AUTOSAR XML (schema 00045)
package /ara/phm
  platform health management contribution phmContrib: process=PhmSample_instance1
    11 x supervision checkpoint:
      engineInitializing: phm-checkpoint=PhmDemo.enginePrototype0.kInitializing
      engineStartupTest: phm-checkpoint=PhmDemo.enginePrototype0.kStartupTest
      engineInitializingFinished: phm-checkpoint=PhmDemo.enginePrototype0.kInitializingFinished
      wheelStarted: phm-checkpoint=PhmDemo.wheelPrototype0.kStarted
      wheelFinished: phm-checkpoint=PhmDemo.wheelPrototype0.kFinished
      wheelStarted: phm-checkpoint=PhmDemo.wheelPrototype1.kStarted
      wheelFinished: phm-checkpoint=PhmDemo.wheelPrototype1.kFinished
      wheelStarted: phm-checkpoint=PhmDemo.wheelPrototype2.kStarted
      wheelFinished: phm-checkpoint=PhmDemo.wheelPrototype2.kFinished
      wheelStarted: phm-checkpoint=PhmDemo.wheelPrototype3.kStarted
      wheelFinished: phm-checkpoint=PhmDemo.wheelPrototype3.kFinished
    global supervision suGlobal: expired-supervision-cycles-tolerance=1, supervision-cycle=0.0
      local supervision suLocal: failed-supervision-cycles-tolerance=0
        alive supervision alive: alive-reference-cycle=600, checkpoint=wheelRunning, expected-alive-indications=6, max-margin=10, min-margin=1
        deadline supervision deadline: checkpoint-transition=transition1, max-deadline=60, min-deadline=40
        logical supervision logical: initial-checkpoint=engineInitializing, final-checkpoint=engineInitializingFinished, transition=[transition1, transition2]
        checkpoint transition transition1: source=engineInitializing, target=engineStartupTest
        checkpoint transition transition2: source=engineStartupTest, target=engineInitializingFinished
        checkpoint transition deadlineTransition: source=phmContrib/wheelStarted, target=phmContrib/wheelFinished
    health channel supervision healthChannel: supervision-condition=IS-OK, supervision=suGlobal
    arbitration arbitration
      logical expression logExp: logical-operator=OR
      rule rule: expression=logExp, rule-init-state=FALSE
    action rec_action
      application action item app_action1: action-type=RESTART, process=PhmSample_instance1
      application action item app_action2: action-type=TERMINATE, process=PhmSample_instance1
      platform action item platform_action1: action-type=RESET-ECU
      platform action item platform_action2: action-type=RESET-MCU
      platform action item platform_action3: action-type=RESET-VM
      watchdog action item watchdog_action: action-type=STOP-TRIGGER
      action list action_list: action-list-execution=TRIGGERED-ON-CHANGE, action-list-item=app_action1
  phm supervised entity interface engine: supervised-entity-id=100
    phm checkpoint kInitializing: checkpoint-id=0
    phm checkpoint kStartupTest: checkpoint-id=1
    phm checkpoint kInitializingFinished: checkpoint-id=2
  phm supervised entity interface wheel: supervised-entity-id=101
    phm checkpoint kStarted: checkpoint-id=0
    phm checkpoint kFinished: checkpoint-id=1
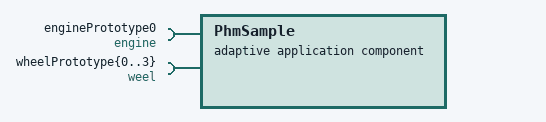
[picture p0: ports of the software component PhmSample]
  adaptive application sw component type PhmSample
    5 x require port:
      enginePrototype0: required-interface=engine
      wheelPrototype{0..3}: required-interface=weel
  executable PhmSampleExe
    root sw component prototype PhmDemo: application-type=PhmSample
  process PhmSample_instance1: executable=PhmSampleExe
